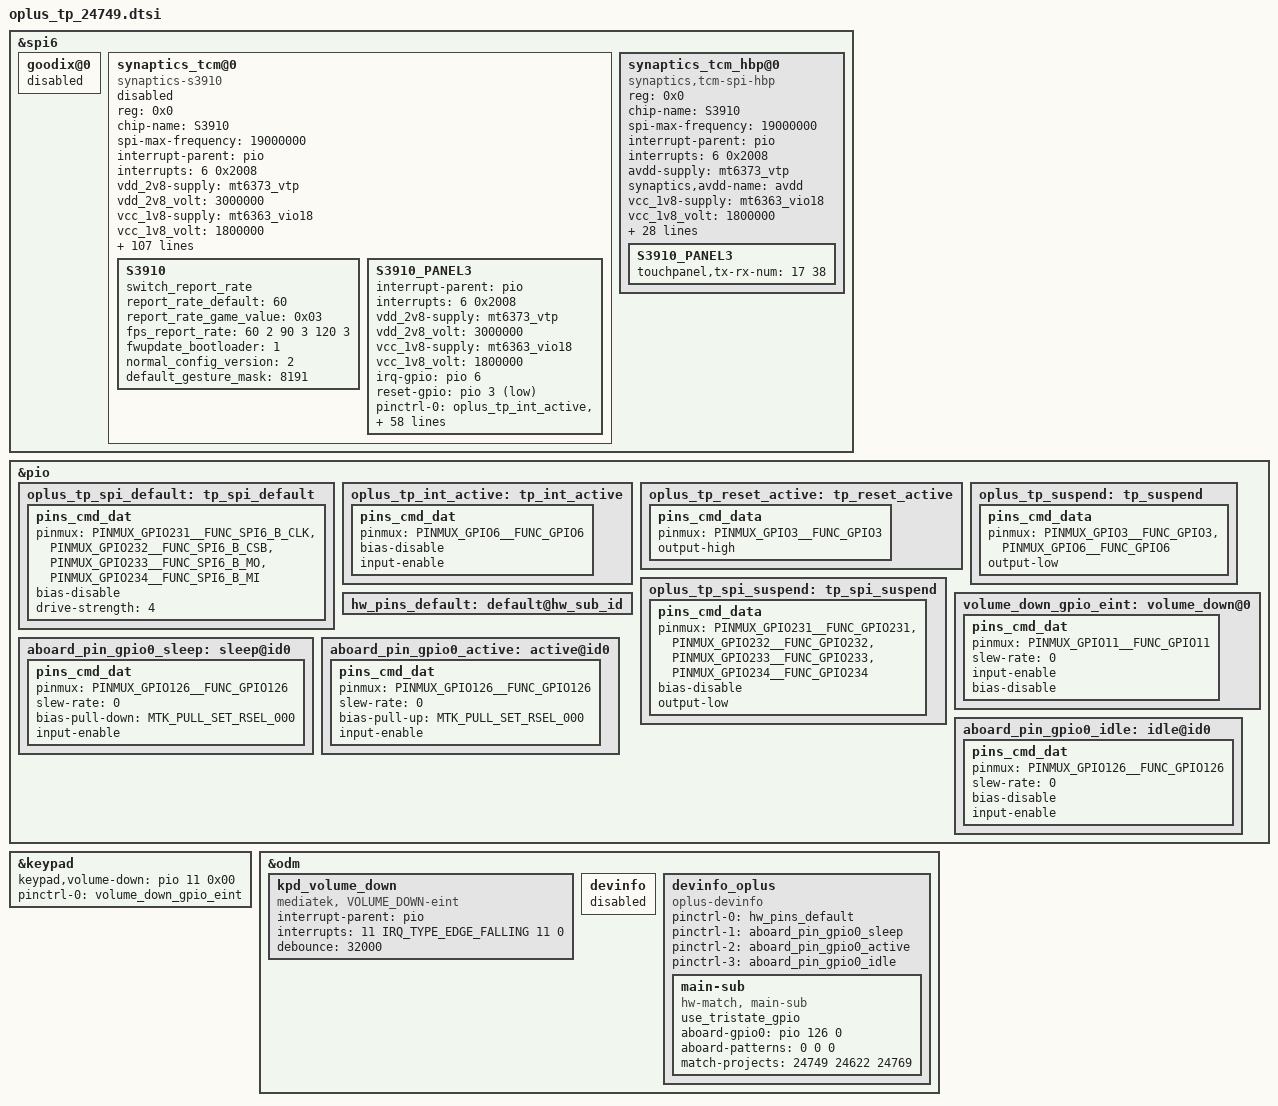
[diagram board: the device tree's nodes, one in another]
// SPDX-License-Identifier: (GPL-2.0 OR MIT)
/*
 * Copyright (C) 2020 MediaTek Inc.
 */

/* TOUCH start */

&spi6 {
	status = "okay";
	#address-cells = <1>;
	#size-cells = <0>;
	goodix@0{
		status = "disabled";
	};
	synaptics_tcm@0{
		compatible = "synaptics-s3910";
		reg = <0x0>;
		chip-name = "S3910";
		status = "disabled";
		spi-max-frequency = <19000000>;
		/* Interrupt && Irq-gpio */
		interrupt-parent = <&pio>;
		interrupts = <6 0x2008>;

		/* Power Config */
		/* enable2v8_gpio  = <&pio 164 0x1>; */
		vdd_2v8-supply = <&mt6373_vtp>;
		vdd_2v8_volt = <3000000>;

		vcc_1v8-supply  = <&mt6363_vio18>;
		vcc_1v8_volt = <1800000>;

		/* Other HW Resource */

		irq-gpio = <&pio 6 0x2008>;
		reset-gpio = <&pio 3 0x1>;
		//cs-gpio = <&pio 110 0x00>;

		pinctrl-names = "default",  "sleep";
		pinctrl-0 = <&oplus_tp_int_active &oplus_tp_reset_active &oplus_tp_spi_default>;
		pinctrl-1 = <&oplus_tp_suspend &oplus_tp_spi_suspend>;

		touchpanel,max-num-support = <10>;
		touchpanel,tx-rx-num = <18 39>;
		touchpanel,panel-coords = <20224 44480>;
		touchpanel,display-coords = <1264 2780>;
		touchpanel,touchmajor-limit = <128 216>;
		touchpanel,elimination-range = <20 200 200>;
		touchpanel,int-mode = <1>; /*0: interrupt and disable, 1:interrupt and not disable*/
		touchpanel,smooth-level = <0 1 2 4 7 9>;
		touchpanel,smooth-level-charging = <0 2 4 7 8 9>;
		touchpanel,sensitive-level = <0 70 55 40 25 10>;
		touchpanel,single-optimized-time = <8>;
		touchpanel,high-frame-rate-time = <60>;

		vid_len = <2>;
		panel_type = <7 3>; /*type:7 TIANMA*/
		platform_support_project = <24749>;
		platform_support_project_dir = <24749>;
		platform_support_project_commandline = "panel_ab948_p_7_a0020_dsi_cmd", "panel_ab946_p_3_a0020_dsi_cmd";

		prevention,curved_screen_V2;
		prevention,grip_disable_level = <6>;
		prevention,updelay_time_ms = <30>;
		prevention,makeup_cnt_weight = <4 1 2 2 2>;
		prevention,large_corner_range = <1380 3400>;
		prevention,large_corner_judge_condition = <500 300 1000 7 7>;
		prevention,trx_reject_condition = <8 7 7>;
		prevention,trx_strict_reject_condition = <8 6 6>;
		prevention,large_judge_time_ms = <500 50 30>;
		prevention,large_exit_condition = <8 8 2>;
		prevention,single_channel_width = <320 320>;
		prevention,normal_tap_condition = <10 350>;
		prevention,long_edge_condition = <179 90 120 80>;
		prevention,long_strict_edge_condition = <160 60>;
		prevention,long_fingerhold_condition = <70 6 4 4>;
		prevention,short_edge_condition = <179 90 120 80>;
		prevention,short_strict_edge_condition = <160 60>;
		prevention,large_strict_exit_condition = <6 6>;
		prevention,top_corner_config = <250 750 1000>;
		prevention,edge_swipe_config = <340 1130>;

		prevention,curved_screen_V4;
		prevention,long_eliminate_point_type = <2 12400 9240 240 27720 300 1>;
		prevention,long_fingerhold_condition2 = <700 2000 0 0>;
		prevention,top_corner_config2 =<3 80 600 1500 0>;
		prevention,hor_long_top_corner_config =<300 2000 0 0>;
		prevention,top_middle_config =<12400 1000 1000 0>;
		prevention,corner_eliminate_point_type =<0 1380 2270 1>;
		prevention,finger_hold_differ_size = <1 0 400 300>;
		prevention,finger_hold_max_rx_exit_distance = <5 350 2300>;
		prevention,max_rx_exit_distance = <1 5 150 350 2000>;
		prevention,dynamic_finger_hold_exit_distance = <1 350 2300 450>;
		prevention,edge_sliding_matched_support = <1 150 3 0>;

		//grip v4.2 reclining mode
		prevention,reclining_mode_support = <1>;
		prevention,long_eliminate_point_type_recli = <2 12400 9240 240 27720 500 1>;
		prevention,finger_hold_differ_size_recli = <1 0 400 400>;
		prevention,finger_hold_max_rx_exit_distance_recli = <5 350 2300>;
		prevention,max_rx_exit_distance_recli = <1 5 100 350 2300>;
		prevention,dynamic_finger_hold_exit_distance_recli = <1 350 2300 450>;
		prevention,edge_sliding_matched_support_recli = <1 150 3 0>;
		prevention,long_edge_condition_recli = <179 90 120 80>;

		/* SW Support Feature Control */
		black_gesture_support;
		sportify_aod_gesture_support;
		pressure_report_support;
		charger_pump_support;
		game_switch_support;
		glove_mode_support;
		smart_gesture_support;
		fw_update_app_support;
		fingerprint_underscreen_support;
		freq_hop_simulate_support;
		report_flow_unlock_support;
		screenoff_fingerprint_info_support;
		irq_need_dev_resume_ok;
		enable_point_auto_change;
		kernel_grip_support;
		//grip_no_driver_support;
		health_monitor_support;
		black_gesture_indep_support;
		snr_read_support;
		palm_to_sleep_support;
		exception_upload_support;
		tp_data_record_support;
		fingerprint_not_report_in_suspend;
		/*
		 *Virtual Key Config:
		 *1:touchpanel,button-type: <virtualkey_type  supportted_button-map>
		 *virtualkey_type:
		 *Type 1: using board_properties
		 *Type 2: using same IC (button zone&& touch zone are seprate)
		 *Type 3: using diffrent IC (button zone&& touch zone are seprate)
		 *Type 4: No need of virtual key process
		 *supportted_button-map:select|menu|home|back
		 *
		 *2:touchpanel,button-map
		 *type (X1,Y1)(X2,Y2)(X3,Y3)(Width_X,Hight_Y)--Only when button-type is 0
		 */
		touchpanel,button-type = <4>;
		touchpanel.button-TRx = <0 0>;

		S3910 {
			switch_report_rate;
			report_rate_default = <60>;
			report_rate_game_value = <0x03>;
			fps_report_rate = <60 2 90 3 120 3>;//1:360Hz 2:125Hz 3:240Hz
			fwupdate_bootloader = <1>;
			normal_config_version = <2>;
			default_gesture_mask = <8191>;
		};
		S3910_PANEL3 {
			interrupt-parent = <&pio>;
			interrupts = <6 0x2008>;

			/* Power Config */
			/* enable2v8_gpio  = <&pio 164 0x1>; */
			vdd_2v8-supply = <&mt6373_vtp>;
			vdd_2v8_volt = <3000000>;

			vcc_1v8-supply  = <&mt6363_vio18>;
			vcc_1v8_volt = <1800000>;

			/* Other HW Resource */

			irq-gpio = <&pio 6 0x2008>;
			reset-gpio = <&pio 3 0x1>;
			//cs-gpio = <&pio 110 0x00>;

			pinctrl-names = "default",  "sleep";
			pinctrl-0 = <&oplus_tp_int_active &oplus_tp_reset_active &oplus_tp_spi_default>;
			pinctrl-1 = <&oplus_tp_suspend &oplus_tp_spi_suspend>;

			touchpanel,max-num-support = <10>;
			touchpanel,tx-rx-num = <17 38>;
			touchpanel,panel-coords = <20224 44480>;
			touchpanel,display-coords = <1264 2780>;
			touchpanel,touchmajor-limit = <128 216>;
			touchpanel,elimination-range = <20 200 200>;
			touchpanel,int-mode = <1>; /*0: interrupt and disable, 1:interrupt and not disable*/
			touchpanel,smooth-level = <0 1 2 4 7 9>;
			touchpanel,smooth-level-charging = <0 2 4 7 8 9>;
			touchpanel,sensitive-level = <0 70 55 40 25 10>;
			touchpanel,single-optimized-time = <8>;
			touchpanel,high-frame-rate-time = <60>;

			prevention,curved_screen_V2;
			prevention,grip_disable_level = <6>;
			prevention,updelay_time_ms = <30>;
			prevention,makeup_cnt_weight = <4 1 2 2 2>;
			prevention,large_corner_range = <1380 3400>;
			prevention,large_corner_judge_condition = <500 300 1000 7 7>;
			prevention,trx_reject_condition = <8 7 7>;
			prevention,trx_strict_reject_condition = <8 6 6>;
			prevention,large_judge_time_ms = <500 50 30>;
			prevention,large_exit_condition = <8 8 2>;
			prevention,single_channel_width = <320 320>;
			prevention,normal_tap_condition = <10 350>;
			prevention,long_edge_condition = <179 90 120 80>;
			prevention,long_strict_edge_condition = <160 60>;
			prevention,long_fingerhold_condition = <70 6 4 4>;
			prevention,short_edge_condition = <179 90 120 80>;
			prevention,short_strict_edge_condition = <160 60>;
			prevention,large_strict_exit_condition = <6 6>;
			prevention,top_corner_config = <250 750 1000>;
			prevention,edge_swipe_config = <340 1130>;

			prevention,curved_screen_V4;
			prevention,long_eliminate_point_type = <2 12400 9240 240 27720 300 1>;
			prevention,long_fingerhold_condition2 = <700 2000 0 0>;
			prevention,top_corner_config2 =<3 80 600 1500 0>;
			prevention,hor_long_top_corner_config =<300 2000 0 0>;
			prevention,top_middle_config =<12400 1000 1000 0>;
			prevention,corner_eliminate_point_type =<0 1380 2270 1>;
			prevention,finger_hold_differ_size = <1 0 400 300>;
			prevention,finger_hold_max_rx_exit_distance = <5 350 2300>;
			prevention,max_rx_exit_distance = <1 5 150 350 2000>;
			prevention,dynamic_finger_hold_exit_distance = <1 350 2300 450>;
			prevention,edge_sliding_matched_support = <1 150 3 0>;
		};
	};

	synaptics_tcm_hbp@0{
		compatible = "synaptics,tcm-spi-hbp";
		reg = <0x0>;
		chip-name = "S3910";
		status = "okay";
		spi-max-frequency = <19000000>;

		/* Interrupt && Irq-gpio */
		interrupt-parent = <&pio>;
		interrupts = <6 0x2008>;

		/* Power Config */
		/* enable2v8_gpio  = <&pio 164 0x1>; */
		/* synaptics,avdd-gpio = <&pio 186 0x1>; */
		avdd-supply = <&mt6373_vtp>;
		synaptics,avdd-name = "avdd";
		vcc_1v8-supply  = <&mt6363_vio18>;
		vcc_1v8_volt = <1800000>;



		/* Other HW Resource */

		synaptics,irq-gpio = <&pio 6 0x2008>;
		synaptics,reset-gpio = <&pio 3 0x1>;
		//cs-gpio = <&pio 110 0x00>;


		pinctrl-names = "default",  "sleep";
		pinctrl-0 = <&oplus_tp_int_active &oplus_tp_reset_active &oplus_tp_spi_default>;
		pinctrl-1 = <&oplus_tp_suspend &oplus_tp_spi_suspend>;

		touchpanel,max-num-support = <10>;
		touchpanel,tx-rx-num = <18 39>;
		touchpanel,panel-coords = <20224 44480>;
		touchpanel,display-coords = <1264 2780>;
		vid_len = <2>;
		panel_type = <7 3>; /*type:7 TIANMA*/
		platform_support_project = <24749>;
		platform_support_project_dir = <24749>;
		platform_support_project_commandline = "panel_ab948_p_7_a0020_dsi_cmd", "panel_ab946_p_3_a0020_dsi_cmd";

		synaptics,power-on-state = <1>;
		synaptics,power-delay-ms = <200>;
		synaptics,irq-on-state = <0>;
		synaptics,reset-on-state = <0>;
		synaptics,reset-active-ms = <10>;
		synaptics,reset-delay-ms = <80>;
		synaptics,spi-mode = <0>;
		synaptics,spi-byte-delay-us = <0>;
		synaptics,spi-block-delay-us = <0>;

		stats_upload_support;
		fingerprint_not_report_in_suspend;
		S3910_PANEL3 {
			touchpanel,tx-rx-num = <17 38>;
		};
	};
};

/*add for Cayman TP*/
&pio {
	oplus_tp_spi_default: tp_spi_default {
		pins_cmd_dat {
		pinmux = <PINMUX_GPIO231__FUNC_SPI6_B_CLK>,
				<PINMUX_GPIO232__FUNC_SPI6_B_CSB>,
				<PINMUX_GPIO233__FUNC_SPI6_B_MO>,
				<PINMUX_GPIO234__FUNC_SPI6_B_MI>;
			bias-disable;
			drive-strength = <4>;
		};
	};
	oplus_tp_int_active: tp_int_active {
		pins_cmd_dat {
			pinmux = <PINMUX_GPIO6__FUNC_GPIO6>;
			bias-disable;
			input-enable;
		};
	};
	oplus_tp_reset_active: tp_reset_active {
		pins_cmd_data {
			pinmux = <PINMUX_GPIO3__FUNC_GPIO3>;
			output-high;
		};
	};
	oplus_tp_suspend: tp_suspend {
		pins_cmd_data {
			pinmux = <PINMUX_GPIO3__FUNC_GPIO3>,
					<PINMUX_GPIO6__FUNC_GPIO6>;
			output-low;
		};
	};
	oplus_tp_spi_suspend: tp_spi_suspend {
		pins_cmd_data {
			pinmux = <PINMUX_GPIO231__FUNC_GPIO231>,
					<PINMUX_GPIO232__FUNC_GPIO232>,
					<PINMUX_GPIO233__FUNC_GPIO233>,
					<PINMUX_GPIO234__FUNC_GPIO234>;
			bias-disable;
			output-low;
		};
	};
};

&keypad {
        keypad,volume-down = <&pio 11 0x00>;
        pinctrl-names = "volume_down_as_int";
        pinctrl-0 = <&volume_down_gpio_eint>;
        status = "okay";
};

&pio {
        volume_down_gpio_eint:volume_down@0{
                pins_cmd_dat {
                        pinmux = <PINMUX_GPIO11__FUNC_GPIO11>;
                        slew-rate = <0>;  /*direction 0:in, 1:out*/
                        input-enable;
                        bias-disable;
                };
        };
};

&odm {
        kpd_volume_down:kpd_volume_down {
                compatible = "mediatek, VOLUME_DOWN-eint";
                interrupt-parent = <&pio>;
                interrupts = <11 IRQ_TYPE_EDGE_FALLING 11 0>;
                debounce = <32000>;
                status = "okay";
        };
};

&odm {
	devinfo {
		status = "disabled";
	};

	devinfo_oplus {
		compatible = "oplus-devinfo";

		pinctrl-names = "default", "aboard_gpio0_sleep", "aboard_gpio0_active", "aboard_gpio0_idle";
		pinctrl-0 = <&hw_pins_default>;
		pinctrl-1 = <&aboard_pin_gpio0_sleep>;
		pinctrl-2 = <&aboard_pin_gpio0_active>;
		pinctrl-3 = <&aboard_pin_gpio0_idle>;

		main-sub {
			compatible = "hw-match, main-sub";
			use_tristate_gpio;
			aboard-gpio0 = <&pio 126 0>;
			aboard-patterns = <0 0 0>;	/*0[high-resistance] 1[pull-down] 2[pull-up]*/
			/*main board*/
			match-projects = <24749 24622 24769>;
		};
	};
};


&pio{
	hw_pins_default:default@hw_sub_id {
	};

	aboard_pin_gpio0_sleep:sleep@id0 {
		pins_cmd_dat {
			pinmux = <PINMUX_GPIO126__FUNC_GPIO126>;
			slew-rate = <0>;
			bias-pull-down = <MTK_PULL_SET_RSEL_000>;
			input-enable;
		};
	};

	aboard_pin_gpio0_active:active@id0 {
		pins_cmd_dat {
			pinmux = <PINMUX_GPIO126__FUNC_GPIO126>;
			slew-rate = <0>;
			bias-pull-up = <MTK_PULL_SET_RSEL_000>;
			input-enable;
		};
	};

	aboard_pin_gpio0_idle:idle@id0 {
		pins_cmd_dat {
			pinmux = <PINMUX_GPIO126__FUNC_GPIO126>;
			slew-rate = <0>;
			bias-disable;
			input-enable;
		};
	};
};


